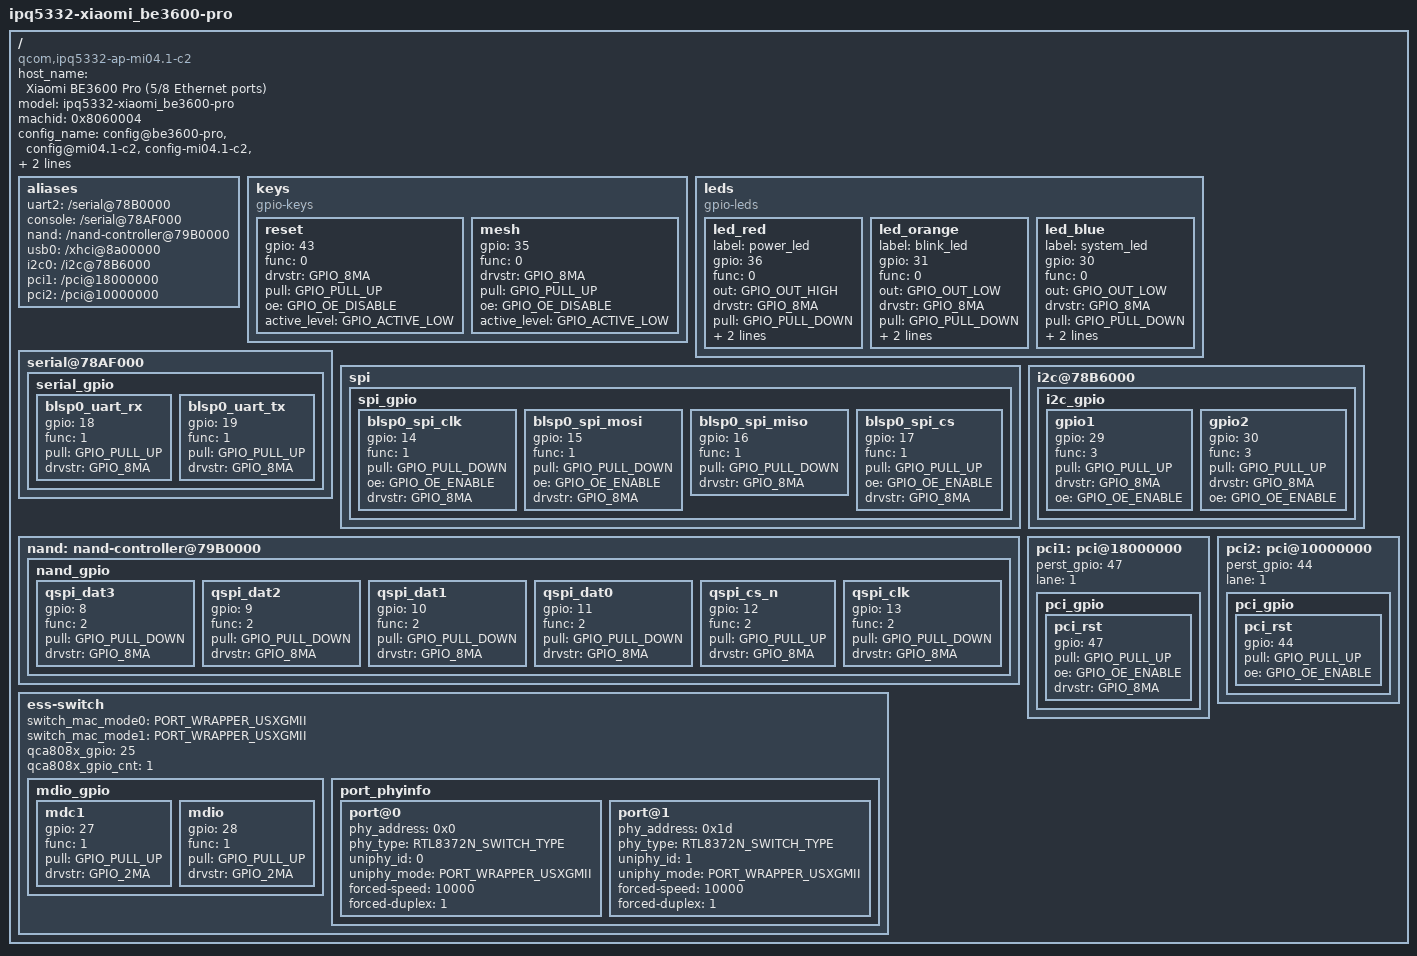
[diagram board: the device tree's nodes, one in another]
/*
 * Copyright (c) 2016-2019, The Linux Foundation. All rights reserved.
 *
 * Copyright (c) 2022-2023 Qualcomm Innovation Center, Inc. All rights reserved.
 *
 * This program is free software; you can redistribute it and/or modify
 * it under the terms of the GNU General Public License version 2 and
 * only version 2 as published by the Free Software Foundation.
 *
 * This program is distributed in the hope that it will be useful,
 * but WITHOUT ANY WARRANTY; without even the implied warranty of
 * MERCHANTABILITY or FITNESS FOR A PARTICULAR PURPOSE.  See the
 * GNU General Public License for more details.
 */

/dts-v1/;
#include "ipq5332-soc.dtsi"
/ {
	host_name = "Xiaomi BE3600 Pro (5/8 Ethernet ports)";
	model = "ipq5332-xiaomi_be3600-pro";
	compatible = "qcom,ipq5332-ap-mi04.1-c2", "qcom,ipq5332";
	machid = <0x8060004>;
	config_name = "config@be3600-pro",
		      "config@mi04.1-c2", "config-mi04.1-c2",
		      "config@rdp478", "config-rdp478",
		      "config@1", "config-1";

	aliases {
		uart2 = "/serial@78B0000";
		console = "/serial@78AF000";
		nand = "/nand-controller@79B0000";
		usb0 = "/xhci@8a00000";
		i2c0 = "/i2c@78B6000";
		pci1 = "/pci@18000000";
		pci2 = "/pci@10000000";
	};

	keys {
		compatible = "gpio-keys";

		reset {
			gpio = <43>;
			func = <0>;
			drvstr = <GPIO_8MA>;
			pull = <GPIO_PULL_UP>;
			oe = <GPIO_OE_DISABLE>;
			active_level = <GPIO_ACTIVE_LOW>;
		};

		mesh {
			gpio = <35>;
			func = <0>;
			drvstr = <GPIO_8MA>;
			pull = <GPIO_PULL_UP>;
			oe = <GPIO_OE_DISABLE>;
			active_level = <GPIO_ACTIVE_LOW>;
		};
	};

	leds {
		compatible = "gpio-leds";

		led_red {
			label = "power_led";
			gpio = <36>;
			func = <0>;
			out = <GPIO_OUT_HIGH>;
			drvstr = <GPIO_8MA>;
			pull = <GPIO_PULL_DOWN>;
			oe = <GPIO_OE_ENABLE>;
			active_level = <GPIO_ACTIVE_HIGH>;
		};

		led_orange {
			label = "blink_led";
			gpio = <31>;
			func = <0>;
			out = <GPIO_OUT_LOW>;
			drvstr = <GPIO_8MA>;
			pull = <GPIO_PULL_DOWN>;
			oe = <GPIO_OE_ENABLE>;
			active_level = <GPIO_ACTIVE_HIGH>;
		};

		led_blue {
			label = "system_led";
			gpio = <30>;
			func = <0>;
			out = <GPIO_OUT_LOW>;
			drvstr = <GPIO_8MA>;
			pull = <GPIO_PULL_DOWN>;
			oe = <GPIO_OE_ENABLE>;
			active_level = <GPIO_ACTIVE_HIGH>;
		};
	};

	serial@78AF000 {
		status = "ok";
		serial_gpio {
			blsp0_uart_rx {
				gpio = <18>;
				func = <1>;
				pull = <GPIO_PULL_UP>;
				drvstr = <GPIO_8MA>;
			};
			blsp0_uart_tx {
				gpio = <19>;
				func = <1>;
				pull = <GPIO_PULL_UP>;
				drvstr = <GPIO_8MA>;
			};
		};
	};

	spi {
		spi_gpio {
			blsp0_spi_clk {
				gpio = <14>;
				func = <1>;
				pull = <GPIO_PULL_DOWN>;
				oe = <GPIO_OE_ENABLE>;
				drvstr = <GPIO_8MA>;
			};
			blsp0_spi_mosi {
				gpio = <15>;
				func = <1>;
				pull = <GPIO_PULL_DOWN>;
				oe = <GPIO_OE_ENABLE>;
				drvstr = <GPIO_8MA>;
			};
			blsp0_spi_miso {
				gpio = <16>;
				func = <1>;
				pull = <GPIO_PULL_DOWN>;
				drvstr = <GPIO_8MA>;
			};
			blsp0_spi_cs {
				gpio = <17>;
				func = <1>;
				pull = <GPIO_PULL_UP>;
				oe = <GPIO_OE_ENABLE>;
				drvstr = <GPIO_8MA>;
			};
		};
	};

	i2c@78B6000 {
		i2c_gpio {
			gpio1 {
				gpio = <29>;
				func = <3>;
				pull = <GPIO_PULL_UP>;
				drvstr = <GPIO_8MA>;
				oe = <GPIO_OE_ENABLE>;
			};

			gpio2 {
				gpio = <30>;
				func = <3>;
				pull = <GPIO_PULL_UP>;
				drvstr = <GPIO_8MA>;
				oe = <GPIO_OE_ENABLE>;
			};
		};
	};

	nand: nand-controller@79B0000 {
		nand_gpio {
			qspi_dat3 {
				gpio = <8>;
				func = <2>;
				pull = <GPIO_PULL_DOWN>;
				drvstr = <GPIO_8MA>;
			};
			qspi_dat2 {
				gpio = <9>;
				func = <2>;
				pull = <GPIO_PULL_DOWN>;
				drvstr = <GPIO_8MA>;
			};
			qspi_dat1 {
				gpio = <10>;
				func = <2>;
				pull = <GPIO_PULL_DOWN>;
				drvstr = <GPIO_8MA>;
			};
			qspi_dat0 {
				gpio = <11>;
				func = <2>;
				pull = <GPIO_PULL_DOWN>;
				drvstr = <GPIO_8MA>;
			};
			qspi_cs_n {
				gpio = <12>;
				func = <2>;
				pull = <GPIO_PULL_UP>;
				drvstr = <GPIO_8MA>;
			};
			qspi_clk {
				gpio = <13>;
				func = <2>;
				pull = <GPIO_PULL_DOWN>;
				drvstr = <GPIO_8MA>;
			};
		};
	};

	pci1: pci@18000000 {
		status = "ok";
		perst_gpio = <47>;
		lane = <1>;
		pci_gpio {
			pci_rst {
				gpio = <47>;
				pull = <GPIO_PULL_UP>;
				oe = <GPIO_OE_ENABLE>;
				drvstr = <GPIO_8MA>;
			};
		};
	};

	pci2: pci@10000000 {
		status = "ok";
		perst_gpio = <44>;
		lane = <1>;
		pci_gpio {
			pci_rst {
				gpio = <44>;
				pull = <GPIO_PULL_UP>;
				oe = <GPIO_OE_ENABLE>;
			};
		};
	};

	ess-switch {
		switch_mac_mode0 = <PORT_WRAPPER_USXGMII>;
		switch_mac_mode1 = <PORT_WRAPPER_USXGMII>;
		/* Runtime detection changes port 1 to RTL8221D on the RP01. */
		/* GPIO25 resets all external Ethernet components together. */
		qca808x_gpio = <25>;
		qca808x_gpio_cnt = <1>;

		mdio_gpio {
			mdc1 {
				gpio = <27>;
				func = <1>;
				pull = <GPIO_PULL_UP>;
				drvstr = <GPIO_2MA>;
			};
			mdio {
				gpio = <28>;
				func = <1>;
				pull = <GPIO_PULL_UP>;
				drvstr = <GPIO_2MA>;
			};
		};

		/* RP02 defaults; RP01 remaps these entries before PPE init. */
		port_phyinfo {
			port@0 {
				phy_address = <0x0>;
				phy_type = <RTL8372N_SWITCH_TYPE>;
				uniphy_id = <0>;
				uniphy_mode = <PORT_WRAPPER_USXGMII>;
				forced-speed = <10000>;
				forced-duplex = <1>;
			};
			port@1 {
				phy_address = <0x1d>;
				phy_type = <RTL8372N_SWITCH_TYPE>;
				uniphy_id = <1>;
				uniphy_mode = <PORT_WRAPPER_USXGMII>;
				forced-speed = <10000>;
				forced-duplex = <1>;
			};
		};
	};
};
